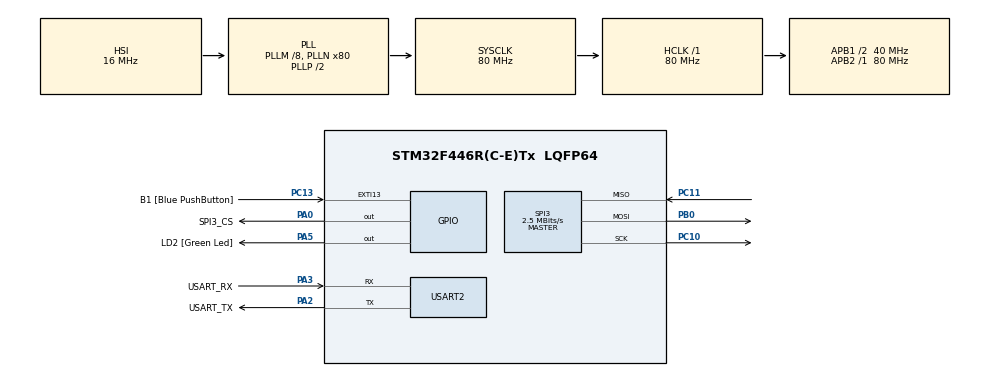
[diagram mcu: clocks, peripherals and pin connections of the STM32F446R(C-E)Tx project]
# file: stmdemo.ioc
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FATFS._MAX_SS=4096
FATFS._USE_LFN=1
Mcu.Family=STM32F4
Mcu.Name=STM32F446R(C-E)Tx
Mcu.Package=LQFP64
NVIC.PriorityGroup=NVIC_PRIORITYGROUP_0
PA0-WKUP.GPIO_Label=SPI3_CS
PA0-WKUP.Signal=GPIO_Output
PA13.GPIO_Label=TMS
PA13.Mode=Serial_Wire
PA13.Signal=SYS_JTMS-SWDIO
PA14.GPIO_Label=TCK
PA14.Mode=Serial_Wire
PA14.Signal=SYS_JTCK-SWCLK
PA2.GPIO_Label=USART_TX
PA2.Mode=Asynchronous
PA2.Signal=USART2_TX
PA3.GPIO_Label=USART_RX
PA3.Mode=Asynchronous
PA3.Signal=USART2_RX
PA5.GPIO_Label=LD2 [Green Led]
PA5.Signal=GPIO_Output
PB0.Mode=Full_Duplex_Master
PB0.Signal=SPI3_MOSI
PB3.GPIO_Label=SWO
PB3.Signal=SYS_JTDO-SWO
PC1.Signal=SPI2_MOSI
PC10.Mode=Full_Duplex_Master
PC10.Signal=SPI3_SCK
PC11.Mode=Full_Duplex_Master
PC11.Signal=SPI3_MISO
PC13.GPIO_Label=B1 [Blue PushButton]
PC13.GPIO_ModeDefaultEXTI=GPIO_MODE_IT_FALLING
PC13.Signal=GPXTI13
PC14-OSC32_IN.Mode=LSE-External-Oscillator
PC14-OSC32_IN.Signal=RCC_OSC32_IN
PC15-OSC32_OUT.Mode=LSE-External-Oscillator
PC15-OSC32_OUT.Signal=RCC_OSC32_OUT
PH0-OSC_IN.Mode=HSE-External-Oscillator
PH0-OSC_IN.Signal=RCC_OSC_IN
PH1-OSC_OUT.Mode=HSE-External-Oscillator
PH1-OSC_OUT.Signal=RCC_OSC_OUT
ProjectManager.HeapSize=0x200
ProjectManager.StackSize=0x400
ProjectManager.TargetToolchain=STM32CubeIDE
RCC.48MHZClocksFreq_Value=84000000
RCC.AHBFreq_Value=80000000
RCC.APB1CLKDivider=RCC_HCLK_DIV2
RCC.APB1Freq_Value=40000000
RCC.APB1TimFreq_Value=80000000
RCC.APB2Freq_Value=80000000
RCC.APB2TimFreq_Value=80000000
RCC.CortexFreq_Value=80000000
RCC.FLatency-AdvancedSettings=FLASH_LATENCY_2
RCC.HCLKFreq_Value=80000000
RCC.HSE_VALUE=8000000
RCC.HSI_VALUE=16000000
RCC.PLLM=8
RCC.PLLN=80
RCC.SYSCLKFreq_VALUE=80000000
RCC.SYSCLKSource=RCC_SYSCLKSOURCE_PLLCLK
RCC.USBFreq_Value=80000000
RCC.VCOOutputFreq_Value=160000000
SPI3.BaudRatePrescaler=SPI_BAUDRATEPRESCALER_16
SPI3.CalculateBaudRate=2.5 MBits/s
SPI3.Direction=SPI_DIRECTION_2LINES
SPI3.Mode=SPI_MODE_MASTER
SPI3.VirtualType=VM_MASTER
USART2.VirtualMode=VM_ASYNC
VP_FATFS_VS_Generic.Mode=User_defined
board=NUCLEO-F446RE

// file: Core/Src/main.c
/* USER CODE BEGIN Header */
/**
  ******************************************************************************
  * @file           : main.c
  * @brief          : Main program body
  ******************************************************************************
  * @attention
  *
  * Copyright (c) 2024 STMicroelectronics.
  * All rights reserved.
  *
  * This software is licensed under terms that can be found in the LICENSE file
  * in the root directory of this software component.
  * If no LICENSE file comes with this software, it is provided AS-IS.
  *
  ******************************************************************************
  */
/* USER CODE END Header */
#include "main.h"
#include "fatfs.h"
#include <stdbool.h>
#include <stdio.h>
#include <string.h>

SPI_HandleTypeDef hspi3;

UART_HandleTypeDef huart2;

/* USER CODE BEGIN PV */
char TxBuffer[250];
/* USER CODE END PV */

void SystemClock_Config(void);
static void MX_GPIO_Init(void);
static void MX_USART2_UART_Init(void);
static void MX_SPI3_Init(void);
static void SD_Card_Test(void);
/* USER CODE BEGIN PFP */
static void UART_Print(char* str)
{
	HAL_UART_Transmit(&huart2, (uint8_t *) str, strlen(str), 100);
}
/* USER CODE END PFP */

int main(void)
{

  /* MCU Configuration--------------------------------------------------------*/

  /* Reset of all peripherals, Initializes the Flash interface and the Systick. */
  HAL_Init();

  /* Configure the system clock */
  SystemClock_Config();

  /* Initialize all configured peripherals */
  MX_GPIO_Init();
  MX_USART2_UART_Init();
  MX_FATFS_Init();
  MX_SPI3_Init();
  /* USER CODE BEGIN 2 */
  //Test The SD Card
  SD_Card_Test();

  /* USER CODE END 2 */

  /* Infinite loop */
  while (1)
  {
	  HAL_GPIO_TogglePin (GPIOA, GPIO_PIN_5);
	  HAL_Delay (100);   /* Insert delay 100 ms */
	  SD_Card_test();
  }
}

void SystemClock_Config(void)
{
  RCC_OscInitTypeDef RCC_OscInitStruct = {0};
  RCC_ClkInitTypeDef RCC_ClkInitStruct = {0};

  /** Configure the main internal regulator output voltage
  */
  __HAL_RCC_PWR_CLK_ENABLE();
  __HAL_PWR_VOLTAGESCALING_CONFIG(PWR_REGULATOR_VOLTAGE_SCALE3);

  /** Initializes the RCC Oscillators according to the specified parameters
  * in the RCC_OscInitTypeDef structure.
  */
  RCC_OscInitStruct.OscillatorType = RCC_OSCILLATORTYPE_HSI;
  RCC_OscInitStruct.HSIState = RCC_HSI_ON;
  RCC_OscInitStruct.HSICalibrationValue = RCC_HSICALIBRATION_DEFAULT;
  RCC_OscInitStruct.PLL.PLLState = RCC_PLL_ON;
  RCC_OscInitStruct.PLL.PLLSource = RCC_PLLSOURCE_HSI;
  RCC_OscInitStruct.PLL.PLLM = 8;
  RCC_OscInitStruct.PLL.PLLN = 80;
  RCC_OscInitStruct.PLL.PLLP = RCC_PLLP_DIV2;
  RCC_OscInitStruct.PLL.PLLQ = 2;
  RCC_OscInitStruct.PLL.PLLR = 2;
  if (HAL_RCC_OscConfig(&RCC_OscInitStruct) != HAL_OK)
  {
    Error_Handler();
  }

  /** Initializes the CPU, AHB and APB buses clocks
  */
  RCC_ClkInitStruct.ClockType = RCC_CLOCKTYPE_HCLK|RCC_CLOCKTYPE_SYSCLK
                              |RCC_CLOCKTYPE_PCLK1|RCC_CLOCKTYPE_PCLK2;
  RCC_ClkInitStruct.SYSCLKSource = RCC_SYSCLKSOURCE_PLLCLK;
  RCC_ClkInitStruct.AHBCLKDivider = RCC_SYSCLK_DIV1;
  RCC_ClkInitStruct.APB1CLKDivider = RCC_HCLK_DIV2;
  RCC_ClkInitStruct.APB2CLKDivider = RCC_HCLK_DIV1;

  if (HAL_RCC_ClockConfig(&RCC_ClkInitStruct, FLASH_LATENCY_2) != HAL_OK)
  {
    Error_Handler();
  }
}

static void SD_Card_Test(void)
{
  FATFS FatFs;
  FIL Fil;
  FRESULT FR_Status;
  FATFS *FS_Ptr;
  UINT RWC, WWC; // Read/Write Word Counter
  DWORD FreeClusters;
  uint32_t TotalSize, FreeSpace;
  char RW_Buffer[200];
  do
  {
    //------------------[ Mount The SD Card ]--------------------
    FR_Status = f_mount(&FatFs, "", 1);
    if (FR_Status != FR_OK)
    {
      sprintf(TxBuffer, "Error! While Mounting SD Card, Error Code: (%i)\r\n", FR_Status);
      UART_Print(TxBuffer);
      break;
    }
    sprintf(TxBuffer, "SD Card Mounted Successfully! \r\n\n");
    UART_Print(TxBuffer);
    //------------------[ Get & Print The SD Card Size & Free Space ]--------------------
    f_getfree("", &FreeClusters, &FS_Ptr);
    TotalSize = (uint32_t)((FS_Ptr->n_fatent - 2) * FS_Ptr->csize * 0.5);
    FreeSpace = (uint32_t)(FreeClusters * FS_Ptr->csize * 0.5);
    sprintf(TxBuffer, "Total SD Card Size: %lu Bytes\r\n", TotalSize);
    UART_Print(TxBuffer);
    sprintf(TxBuffer, "Free SD Card Space: %lu Bytes\r\n\n", FreeSpace);
    UART_Print(TxBuffer);
    //------------------[ Open A Text File For Write & Write Data ]--------------------
    //Open the file
    FR_Status = f_open(&Fil, "TextFileWrite.txt", FA_WRITE | FA_READ | FA_CREATE_ALWAYS);
    if(FR_Status != FR_OK)
    {
      sprintf(TxBuffer, "Error! While Creating/Opening A New Text File, Error Code: (%i)\r\n", FR_Status);
      UART_Print(TxBuffer);
      break;
    }
    sprintf(TxBuffer, "Text File Created & Opened! Writing Data To The Text File..\r\n\n");
    UART_Print(TxBuffer);
    // (1) Write Data To The Text File [ Using f_puts() Function ]
    f_puts("Hello! From STM32 To SD Card Over SPI, Using f_puts()\n", &Fil);
    // (2) Write Data To The Text File [ Using f_write() Function ]
    strcpy(RW_Buffer, "Hello! From STM32 To SD Card Over SPI, Using f_write()\r\n");
    f_write(&Fil, RW_Buffer, strlen(RW_Buffer), &WWC);
    // Close The File
    f_close(&Fil);
    //------------------[ Open A Text File For Read & Read Its Data ]--------------------
    // Open The File
    FR_Status = f_open(&Fil, "TextFileWrite.txt", FA_READ);
    if(FR_Status != FR_OK)
    {
      sprintf(TxBuffer, "Error! While Opening (TextFileWrite.txt) File For Read.. \r\n");
      UART_Print(TxBuffer);
      break;
    }
    // (1) Read The Text File's Data [ Using f_gets() Function ]
    f_gets(RW_Buffer, sizeof(RW_Buffer), &Fil);
    sprintf(TxBuffer, "Data Read From (TextFileWrite.txt) Using f_gets():%s", RW_Buffer);
    UART_Print(TxBuffer);
    // (2) Read The Text File's Data [ Using f_read() Function ]
    f_read(&Fil, RW_Buffer, f_size(&Fil), &RWC);
    sprintf(TxBuffer, "Data Read From (TextFileWrite.txt) Using f_read():%s", RW_Buffer);
    UART_Print(TxBuffer);
    // Close The File
    f_close(&Fil);
    sprintf(TxBuffer, "File Closed! \r\n\n");
    UART_Print(TxBuffer);
    //------------------[ Open An Existing Text File, Update Its Content, Read It Back ]--------------------
    // (1) Open The Existing File For Write (Update)
    FR_Status = f_open(&Fil, "TextFileWrite.txt", FA_OPEN_EXISTING | FA_WRITE);
    FR_Status = f_lseek(&Fil, f_size(&Fil)); // Move The File Pointer To The EOF (End-Of-File)
    if(FR_Status != FR_OK)
    {
      sprintf(TxBuffer, "Error! While Opening (TextFileWrite.txt) File For Update.. \r\n");
      UART_Print(TxBuffer);
      break;
    }
    // (2) Write New Line of Text Data To The File
    FR_Status = f_puts("This New Line Was Added During Update!\r\n", &Fil);
    f_close(&Fil);
    memset(RW_Buffer,'\0',sizeof(RW_Buffer)); // Clear The Buffer
    // (3) Read The Contents of The Text File After The Update
    FR_Status = f_open(&Fil, "TextFileWrite.txt", FA_READ); // Open The File For Read
    f_read(&Fil, RW_Buffer, f_size(&Fil), &RWC);
    sprintf(TxBuffer, "Data Read From (TextFileWrite.txt) After Update:%s", RW_Buffer);
    UART_Print(TxBuffer);
    f_close(&Fil);
    //------------------[ Delete The Text File ]--------------------
    // Delete The File
    /*
    FR_Status = f_unlink(TextFileWrite.txt);
    if (FR_Status != FR_OK){
        sprintf(TxBuffer, "Error! While Deleting The (TextFileWrite.txt) File.. \r\n");
        UART_Print(TxBuffer);
    }
    */
  } while(0);
  //------------------[ Test Complete! Unmount The SD Card ]--------------------
  FR_Status = f_mount(NULL, "", 0);
  if (FR_Status != FR_OK)
  {
      sprintf(TxBuffer, "Error! While Un-mounting SD Card, Error Code: (%i)\r\n", FR_Status);
      UART_Print(TxBuffer);
  } else{
      sprintf(TxBuffer, "SD Card Un-mounted Successfully! \r\n");
      UART_Print(TxBuffer);
  }
}

static void MX_SPI3_Init(void)
{

  /* SPI3 parameter configuration*/
  hspi3.Instance = SPI3;
  hspi3.Init.Mode = SPI_MODE_MASTER;
  hspi3.Init.Direction = SPI_DIRECTION_2LINES;
  hspi3.Init.DataSize = SPI_DATASIZE_8BIT;
  hspi3.Init.CLKPolarity = SPI_POLARITY_LOW;
  hspi3.Init.CLKPhase = SPI_PHASE_1EDGE;
  hspi3.Init.NSS = SPI_NSS_SOFT;
  hspi3.Init.BaudRatePrescaler = SPI_BAUDRATEPRESCALER_16;
  hspi3.Init.FirstBit = SPI_FIRSTBIT_MSB;
  hspi3.Init.TIMode = SPI_TIMODE_DISABLE;
  hspi3.Init.CRCCalculation = SPI_CRCCALCULATION_DISABLE;
  hspi3.Init.CRCPolynomial = 10;
  if (HAL_SPI_Init(&hspi3) != HAL_OK)
  {
    Error_Handler();
  }

}

static void MX_USART2_UART_Init(void)
{

  huart2.Instance = USART2;
  huart2.Init.BaudRate = 115200;
  huart2.Init.WordLength = UART_WORDLENGTH_8B;
  huart2.Init.StopBits = UART_STOPBITS_1;
  huart2.Init.Parity = UART_PARITY_NONE;
  huart2.Init.Mode = UART_MODE_TX_RX;
  huart2.Init.HwFlowCtl = UART_HWCONTROL_NONE;
  huart2.Init.OverSampling = UART_OVERSAMPLING_16;
  if (HAL_UART_Init(&huart2) != HAL_OK)
  {
    Error_Handler();
  }

}

static void MX_GPIO_Init(void)
{
  GPIO_InitTypeDef GPIO_InitStruct = {0};

  /* GPIO Ports Clock Enable */
  __HAL_RCC_GPIOC_CLK_ENABLE();
  __HAL_RCC_GPIOH_CLK_ENABLE();
  __HAL_RCC_GPIOA_CLK_ENABLE();
  __HAL_RCC_GPIOB_CLK_ENABLE();

  /*Configure GPIO pin Output Level */
  HAL_GPIO_WritePin(GPIOA, SPI3_CS_Pin|LD2_Pin, GPIO_PIN_RESET);

  /*Configure GPIO pin : B1_Pin */
  GPIO_InitStruct.Pin = B1_Pin;
  GPIO_InitStruct.Mode = GPIO_MODE_IT_FALLING;
  GPIO_InitStruct.Pull = GPIO_NOPULL;
  HAL_GPIO_Init(B1_GPIO_Port, &GPIO_InitStruct);

  /*Configure GPIO pin : PC1 */
  GPIO_InitStruct.Pin = GPIO_PIN_1;
  GPIO_InitStruct.Mode = GPIO_MODE_AF_PP;
  GPIO_InitStruct.Pull = GPIO_NOPULL;
  GPIO_InitStruct.Speed = GPIO_SPEED_FREQ_VERY_HIGH;
  GPIO_InitStruct.Alternate = GPIO_AF7_SPI2;
  HAL_GPIO_Init(GPIOC, &GPIO_InitStruct);

  /*Configure GPIO pins : SPI3_CS_Pin LD2_Pin */
  GPIO_InitStruct.Pin = SPI3_CS_Pin|LD2_Pin;
  GPIO_InitStruct.Mode = GPIO_MODE_OUTPUT_PP;
  GPIO_InitStruct.Pull = GPIO_NOPULL;
  GPIO_InitStruct.Speed = GPIO_SPEED_FREQ_LOW;
  HAL_GPIO_Init(GPIOA, &GPIO_InitStruct);

}

void Error_Handler(void)
{
  __disable_irq();
  while (1)
  {
  }
}
